# MSP432P401M register map
Vendor: Texas Instruments; File version: 3.230
Registers are 32-bit, read-write, reset 0x0 unless marked. A register's access mark holds for its fields unless they carry their own. Offsets are from the block's base; [hi:lo] are bit positions; {n}, {i} and the like mark numbered series.

## COMP_E0
Base 0x40003400
Same registers: COMP_E1 0x40003800
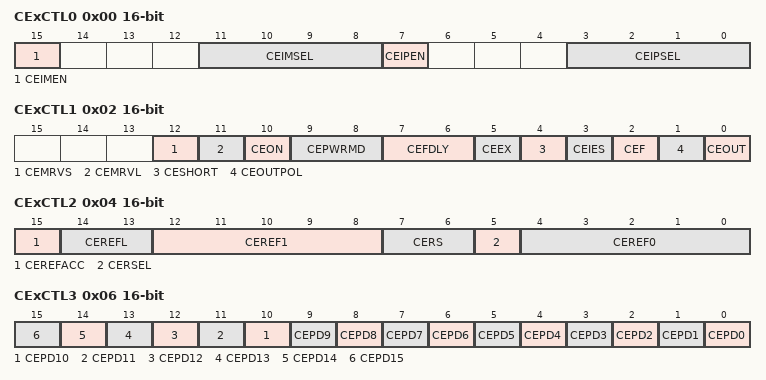
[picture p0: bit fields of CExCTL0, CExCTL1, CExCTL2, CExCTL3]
0x00 CExCTL0 16-bit — Comparator Control Register 0
  [15] CEIMEN — Channel input enable for the - terminal
    0=Selected analog input channel for V- terminal is disabled; 1=Selected analog input channel for V- terminal is enabled
  [11:8] CEIMSEL — Channel input selected for the - terminal
    {v}=Channel {v} selected (v=0..15)
  [7] CEIPEN — Channel input enable for the V+ terminal
    0=Selected analog input channel for V+ terminal is disabled; 1=Selected analog input channel for V+ terminal is enabled
  [3:0] CEIPSEL — Channel input selected for the V+ terminal
    {v}=Channel {v} selected (v=0..15)
0x02 CExCTL1 16-bit — Comparator Control Register 1
  [12] CEMRVS — This bit defines if the comparator output selects between VREF0 or VREF1 if CERS = 00, 01, or 10.
    0=Comparator output state selects between VREF0 or VREF1; 1=CEMRVL selects between VREF0 or VREF1
  [11] CEMRVL — This bit is valid of CEMRVS is set to 1
    0=VREF0 is selected if CERS = 00, 01, or 10; 1=VREF1 is selected if CERS = 00, 01, or 10
  [10] CEON — Comparator On
    0=Off; 1=On
  [9:8] CEPWRMD — Power Mode
    0=High-speed mode; 1=Normal mode; 2=Ultra-low power mode
  [7:6] CEFDLY — Filter delay
    0=Typical filter delay of TBD (450) ns; 1=Typical filter delay of TBD (900) ns; 2=Typical filter delay of TBD (1800) ns; 3=Typical filter delay of TBD (3600) ns
  [5] CEEX — Exchange
  [4] CESHORT — Input short
    0=Inputs not shorted; 1=Inputs shorted
  [3] CEIES — Interrupt edge select for CEIIFG and CEIFG
    0=Rising edge for CEIFG, falling edge for CEIIFG; 1=Falling edge for CEIFG, rising edge for CEIIFG
  [2] CEF — Comparator output filter
    0=Comparator output is not filtered; 1=Comparator output is filtered
  [1] CEOUTPOL — Comparator output polarity
    0=Noninverted; 1=Inverted
  [0] CEOUT — Comparator output value
0x04 CExCTL2 16-bit — Comparator Control Register 2
  [15] CEREFACC — Reference accuracy
    0=Static mode; 1=Clocked (low power, low accuracy) mode
  [14:13] CEREFL — Reference voltage level
    0=Reference amplifier is disabled. No reference voltage is requested; 1=1.2 V is selected as shared reference voltage input; 2=2.0 V is selected as shared reference voltage input; 3=2.5 V is selected as shared reference voltage input
  [12:8] CEREF1 — Reference resistor tap 1
    {v}=Reference resistor tap for setting {v} (v=0..31)
  [7:6] CERS — Reference source
    0=No current is drawn by the reference circuitry; 1=VCC applied to the resistor ladder; 2=Shared reference voltage applied to the resistor ladder; 3=Shared reference voltage supplied to V(CREF). Resistor ladder is off
  [5] CERSEL — Reference select
    0=When CEEX = 0, VREF is applied to the V+ terminal; When CEEX = 1, VREF is applied to the V- terminal; 1=When CEEX = 0, VREF is applied to the V- terminal; When CEEX = 1, VREF is applied to the V+ terminal
  [4:0] CEREF0 — Reference resistor tap 0
    {v}=Reference resistor tap for setting {v} (v=0..31)
0x06 CExCTL3 16-bit — Comparator Control Register 3
  [all] fields
    0=The input buffer is enabled; 1=The input buffer is disabled
  [n] CEPD{n} (n=0..15) — Port disable
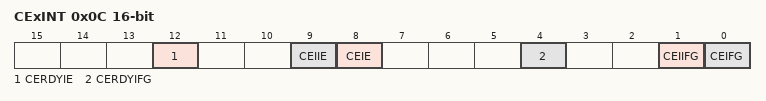
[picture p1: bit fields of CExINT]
0x0C CExINT 16-bit — Comparator Interrupt Control Register
  [12] CERDYIE — Comparator ready interrupt enable
    0=Interrupt disabled; 1=Interrupt enabled
  [9] CEIIE — Comparator output interrupt enable inverted polarity
    0=Interrupt disabled; 1=Interrupt enabled
  [8] CEIE — Comparator output interrupt enable
    0=Interrupt disabled; 1=Interrupt enabled
  [4] CERDYIFG — Comparator ready interrupt flag
    0=No interrupt pending; 1=Interrupt pending
  [1] CEIIFG — Comparator output inverted interrupt flag
    0=No interrupt pending; 1=Interrupt pending
  [0] CEIFG — Comparator output interrupt flag
    0=No interrupt pending; 1=Interrupt pending
0x0E CExIV 16-bit ro — Comparator Interrupt Vector Word Register
  [15:0] CEIV — Comparator interrupt vector word register
    on read: 0=No interrupt pending; 2=Interrupt Source: CEOUT interrupt; Interrupt Flag: CEIFG; Interrupt Priority: Highest; 4=Interrupt Source: CEOUT interrupt inverted polarity; Interrupt Flag: CEIIFG; 10=Interrupt Source: Comparator ready interrupt; Interrupt Flag: CERDYIFG; Interrupt Priority: Lowest
